# STM32H743 register map
File version: 2.4
CPU: CM7 r0p1, little endian, MPU, FPU, 4 interrupt priority bits
Registers are 32-bit, read-write, reset 0x0 unless marked. A register's access mark holds for its fields unless they carry their own. Offsets are from the block's base; [hi:lo] are bit positions; {n}, {i} and the like mark numbered series.

## DMA1 — DMA 控制器
Base 0x40020000
Same registers: DMA2 0x40020400
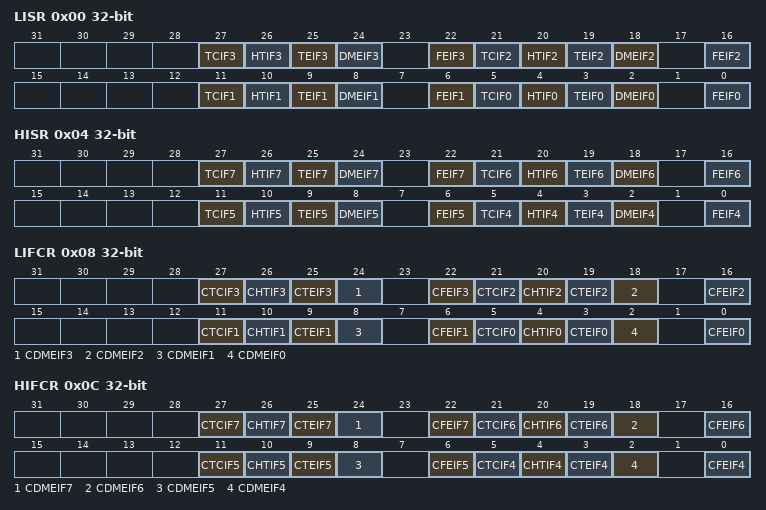
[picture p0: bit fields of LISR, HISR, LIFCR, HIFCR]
0x00 LISR ro — 低中断状态寄存器
  [27] TCIF3 — 流 x 传输完成中断标志（x = 3..0）
  [26] HTIF3 — 流 x 半传输完成中断标志（x = 3..0）
  [25] TEIF3 — 流 x 传输错误中断标志（x = 3..0）
  [24] DMEIF3 — 流 x 直接模式错误中断标志（x = 3..0）
  [22] FEIF3 — 流 x FIFO 错误中断标志（x = 3..0）
  [21] TCIF2 — 流 x 传输完成中断标志（x = 3..0）
  [20] HTIF2 — 流 x 半传输完成中断标志（x = 3..0）
  [19] TEIF2 — 流 x 传输错误中断标志（x = 3..0）
  [18] DMEIF2 — 流 x 直接模式错误中断标志（x = 3..0）
  [16] FEIF2 — 流 x FIFO 错误中断标志（x = 3..0）
  [11] TCIF1 — 流 x 传输完成中断标志（x = 3..0）
  [10] HTIF1 — 流 x 半传输完成中断标志（x = 3..0）
  [9] TEIF1 — 流 x 传输错误中断标志（x = 3..0）
  [8] DMEIF1 — 流 x 直接模式错误中断标志（x = 3..0）
  [6] FEIF1 — 流 x FIFO 错误中断标志（x = 3..0）
  [5] TCIF0 — 流 x 传输完成中断标志（x = 3..0）
  [4] HTIF0 — 流 x 半传输完成中断标志（x = 3..0）
  [3] TEIF0 — 流 x 传输错误中断标志（x = 3..0）
  [2] DMEIF0 — 流 x 直接模式错误中断标志（x = 3..0）
  [0] FEIF0 — 流 x FIFO 错误中断标志（x = 3..0）
0x04 HISR ro — 高中断状态寄存器
  [27] TCIF7 — 流 x 传输完成中断标志（x = 7..4）
  [26] HTIF7 — 流 x 半传输完成中断标志（x = 7..4）
  [25] TEIF7 — 流 x 传输错误中断标志（x = 7..4）
  [24] DMEIF7 — 流 x 直接模式错误中断标志（x = 7..4）
  [22] FEIF7 — 流 x FIFO 错误中断标志（x = 7..4）
  [21] TCIF6 — 流 x 传输完成中断标志（x = 7..4）
  [20] HTIF6 — 流 x 半传输完成中断标志（x = 7..4）
  [19] TEIF6 — 流 x 传输错误中断标志（x = 7..4）
  [18] DMEIF6 — 流 x 直接模式错误中断标志（x = 7..4）
  [16] FEIF6 — 流 x FIFO 错误中断标志（x = 7..4）
  [11] TCIF5 — 流 x 传输完成中断标志（x = 7..4）
  [10] HTIF5 — 流 x 半传输完成中断标志（x = 7..4）
  [9] TEIF5 — 流 x 传输错误中断标志（x = 7..4）
  [8] DMEIF5 — 流 x 直接模式错误中断标志（x = 7..4）
  [6] FEIF5 — 流 x FIFO 错误中断标志（x = 7..4）
  [5] TCIF4 — 流 x 传输完成中断标志（x = 7..4）
  [4] HTIF4 — 流 x 半传输完成中断标志（x = 7..4）
  [3] TEIF4 — 流 x 传输错误中断标志（x = 7..4）
  [2] DMEIF4 — 流 x 直接模式错误中断标志（x = 7..4）
  [0] FEIF4 — 流 x FIFO 错误中断标志（x = 7..4）
0x08 LIFCR — 低中断标志清除寄存器
  [27] CTCIF3 — 流 x 清除传输完成中断标志（x = 3..0）
  [26] CHTIF3 — 流 x 清除半传输完成中断标志（x = 3..0）
  [25] CTEIF3 — 流 x 清除传输错误中断标志（x = 3..0）
  [24] CDMEIF3 — 流 x 清除直接模式错误中断标志（x = 3..0）
  [22] CFEIF3 — 流 x 清除 FIFO 错误中断标志（x = 3..0）
  [21] CTCIF2 — 流 x 清除传输完成中断标志（x = 3..0）
  [20] CHTIF2 — 流 x 清除半传输完成中断标志（x = 3..0）
  [19] CTEIF2 — 流 x 清除传输错误中断标志（x = 3..0）
  [18] CDMEIF2 — 流 x 清除直接模式错误中断标志（x = 3..0）
  [16] CFEIF2 — 流 x 清除 FIFO 错误中断标志（x = 3..0）
  [11] CTCIF1 — 流 x 清除传输完成中断标志（x = 3..0）
  [10] CHTIF1 — 流 x 清除半传输完成中断标志（x = 3..0）
  [9] CTEIF1 — 流 x 清除传输错误中断标志（x = 3..0）
  [8] CDMEIF1 — 流 x 清除直接模式错误中断标志（x = 3..0）
  [6] CFEIF1 — 流 x 清除 FIFO 错误中断标志（x = 3..0）
  [5] CTCIF0 — 流 x 清除传输完成中断标志（x = 3..0）
  [4] CHTIF0 — 流 x 清除半传输完成中断标志（x = 3..0）
  [3] CTEIF0 — 流 x 清除传输错误中断标志（x = 3..0）
  [2] CDMEIF0 — 流 x 清除直接模式错误中断标志（x = 3..0）
  [0] CFEIF0 — 流 x 清除 FIFO 错误中断标志（x = 3..0）
0x0C HIFCR — 高中断标志清除寄存器
  [27] CTCIF7 — 流 x 清除传输完成中断标志（x = 7..4）
  [26] CHTIF7 — 流 x 清除半传输完成中断标志（x = 7..4）
  [25] CTEIF7 — 流 x 清除传输错误中断标志（x = 7..4）
  [24] CDMEIF7 — 流 x 清除直接模式错误中断标志（x = 7..4）
  [22] CFEIF7 — 流 x 清除 FIFO 错误中断标志（x = 7..4）
  [21] CTCIF6 — 流 x 清除传输完成中断标志（x = 7..4）
  [20] CHTIF6 — 流 x 清除半传输完成中断标志（x = 7..4）
  [19] CTEIF6 — 流 x 清除传输错误中断标志（x = 7..4）
  [18] CDMEIF6 — 流 x 清除直接模式错误中断标志（x = 7..4）
  [16] CFEIF6 — 流 x 清除 FIFO 错误中断标志（x = 7..4）
  [11] CTCIF5 — 流 x 清除传输完成中断标志（x = 7..4）
  [10] CHTIF5 — 流 x 清除半传输完成中断标志（x = 7..4）
  [9] CTEIF5 — 流 x 清除传输错误中断标志（x = 7..4）
  [8] CDMEIF5 — 流 x 清除直接模式错误中断标志（x = 7..4）
  [6] CFEIF5 — 流 x 清除 FIFO 错误中断标志（x = 7..4）
  [5] CTCIF4 — 流 x 清除传输完成中断标志（x = 7..4）
  [4] CHTIF4 — 流 x 清除半传输完成中断标志（x = 7..4）
  [3] CTEIF4 — 流 x 清除传输错误中断标志（x = 7..4）
  [2] CDMEIF4 — 流 x 清除直接模式错误中断标志（x = 7..4）
  [0] CFEIF4 — 流 x 清除 FIFO 错误中断标志（x = 7..4）
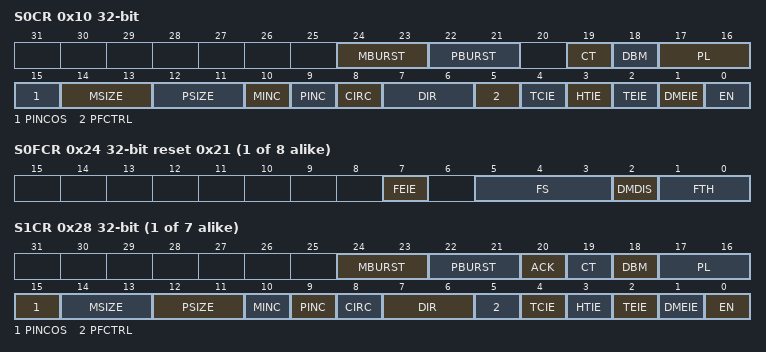
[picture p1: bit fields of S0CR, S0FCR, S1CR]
0x10 S0CR — 流 x 配置寄存器
  [24:23] MBURST — 存储器突发传输配置
  [22:21] PBURST — 外设突发传输配置
  [19] CT — 当前目标（仅在双缓冲模式下有效）
  [18] DBM — 双缓冲模式
  [17:16] PL — 优先级
  [15] PINCOS — 外设增量偏移大小
  [14:13] MSIZE — 存储器数据宽度
  [12:11] PSIZE — 外设数据宽度
  [10] MINC — 存储器增量模式
  [9] PINC — 外设增量模式
  [8] CIRC — 循环模式
  [7:6] DIR — 数据传输方向
  [5] PFCTRL — 外设流控制器
  [4] TCIE — 传输完成中断使能
  [3] HTIE — 半传输完成中断使能
  [2] TEIE — 传输错误中断使能
  [1] DMEIE — 直接模式错误中断使能
  [0] EN — 流使能 / 读为低时表示流就绪标志
{0x14+0x18*i} S{i}NDTR (i=0..7) — 流 x 数据数量寄存器
  [15:0] NDT — 待传输的数据项数量
{0x18+0x18*i} S{i}PAR (i=0..7) — 流 x 外设地址寄存器
  [31:0] PA — 外设地址
{0x1C+0x18*i} S{i}M0AR (i=0..7) — 流 x 存储器 0 地址寄存器
  [31:0] M0A — 存储器 0 地址
{0x20+0x18*i} S{i}M1AR (i=0..7) — 流 x 存储器 1 地址寄存器
  [31:0] M1A — 存储器 1 地址（用于双缓冲模式）
{0x24+0x18*i} S{i}FCR access per field reset 0x21 (i=0..7) — 流 x FIFO 控制寄存器
  [7] FEIE rw — FIFO 错误中断使能
  [5:3] FS ro — FIFO 状态
  [2] DMDIS rw — 直接模式禁用
  [1:0] FTH rw — FIFO 阈值选择
{0x10+0x18*i} S{i}CR (i=1..7) — 流 x 配置寄存器
  [24:23] MBURST — 存储器突发传输配置
  [22:21] PBURST — 外设突发传输配置
  [20] ACK
  [19] CT — 当前目标（仅在双缓冲模式下有效）
  [18] DBM — 双缓冲模式
  [17:16] PL — 优先级
  [15] PINCOS — 外设增量偏移大小
  [14:13] MSIZE — 存储器数据宽度
  [12:11] PSIZE — 外设数据宽度
  [10] MINC — 存储器增量模式
  [9] PINC — 外设增量模式
  [8] CIRC — 循环模式
  [7:6] DIR — 数据传输方向
  [5] PFCTRL — 外设流控制器
  [4] TCIE — 传输完成中断使能
  [3] HTIE — 半传输完成中断使能
  [2] TEIE — 传输错误中断使能
  [1] DMEIE — 直接模式错误中断使能
  [0] EN — 流使能 / 读为低时表示流就绪标志
